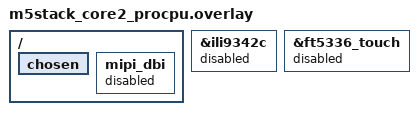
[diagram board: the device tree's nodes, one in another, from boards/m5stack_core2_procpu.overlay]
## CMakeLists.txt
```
# SPDX-License-Identifier: Apache-2.0

cmake_minimum_required(VERSION 3.20.0)

find_package(Zephyr REQUIRED HINTS $ENV{ZEPHYR_BASE})
project(dynamic_web)

zephyr_linker_sources(SECTIONS sections-rom.ld)
zephyr_linker_section(NAME http_resource_desc_web_http_service KVMA RAM_REGION GROUP RODATA_REGION)

set(gen_dir ${ZEPHYR_BINARY_DIR}/include/generated)
generate_inc_file_for_target(app web/index.html ${gen_dir}/web_index_html.inc)
generate_inc_file_for_target(app web/styles.css ${gen_dir}/web_styles_css.inc)
generate_inc_file_for_target(app web/app.js ${gen_dir}/web_app_js.inc)
generate_inc_file_for_target(app web/vendor/bootstrap/css/bootstrap.min.css ${gen_dir}/web_bootstrap_min_css_gz.inc --gzip)
generate_inc_file_for_target(app web/vendor/bootstrap/js/bootstrap.bundle.min.js ${gen_dir}/web_bootstrap_bundle_min_js_gz.inc --gzip)

target_sources(app PRIVATE
  src/app_utils.c
  src/main.c
  src/wifi_service.c
  src/filesystem_service.c
  src/webserver_service.c
)
```

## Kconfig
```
source "Kconfig.zephyr"

menu "dynamic_web options"

choice APP_WEB_CONTENT_SOURCE
	prompt "Web content source"
	default APP_WEB_CONTENT_FROM_FILESYSTEM

config APP_WEB_CONTENT_FROM_FILESYSTEM
	bool "Serve web files from LittleFS (/lfs/www)"

config APP_WEB_CONTENT_FROM_FIRMWARE
	bool "Serve web files directly from firmware image"

endchoice

config APP_SYNC_WEB_FILES_ON_BOOT
	bool "Sync embedded web files to LittleFS at boot"
	default y
	depends on APP_WEB_CONTENT_FROM_FILESYSTEM
	help
	  When enabled, website assets embedded in firmware are written
	  to /lfs/www on each boot. Disable this if you plan to update
	  files directly in LittleFS (e.g. via mcumgr) and want to keep
	  those changes across reboot.

endmenu
```

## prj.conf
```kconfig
CONFIG_MAIN_STACK_SIZE=6144

CONFIG_LOG=y
CONFIG_THREAD_RUNTIME_STATS=y
CONFIG_SCHED_THREAD_USAGE_ALL=y
CONFIG_SYS_HEAP_RUNTIME_STATS=y

CONFIG_NETWORKING=y
CONFIG_NET_MGMT=y
CONFIG_NET_MGMT_EVENT=y
CONFIG_NET_MGMT_EVENT_INFO=y
CONFIG_NET_CONNECTION_MANAGER=y
CONFIG_NET_IPV4=y
CONFIG_NET_TCP=y
CONFIG_NET_UDP=y
CONFIG_NET_SOCKETS=y
CONFIG_NET_DHCPV4=y

CONFIG_WIFI=y
CONFIG_NET_L2_WIFI_MGMT=y

CONFIG_HTTP_SERVER=y
CONFIG_HTTP_SERVER_RESOURCE_WILDCARD=y
CONFIG_HTTP_SERVER_COMPRESSION=y
CONFIG_HTTP_SERVER_NUM_SERVICES=1
CONFIG_HTTP_SERVER_MAX_CLIENTS=4
CONFIG_HTTP_SERVER_CLIENT_BUFFER_SIZE=2048

CONFIG_POSIX_API=y
CONFIG_EVENTFD=y
CONFIG_FDTABLE=y
CONFIG_ZVFS_POLL_MAX=16

CONFIG_FLASH=y
CONFIG_FLASH_MAP=y
CONFIG_FILE_SYSTEM=y
CONFIG_FILE_SYSTEM_MKFS=y
CONFIG_FILE_SYSTEM_LITTLEFS=y

CONFIG_ZCBOR=y
CONFIG_MCUMGR=y
CONFIG_MCUMGR_GRP_FS=y
CONFIG_MCUMGR_GRP_OS=y
CONFIG_BASE64=y
CONFIG_CRC=y
# CONFIG_MCUMGR_TRANSPORT_UART is not set
CONFIG_MCUMGR_TRANSPORT_SHELL=y
CONFIG_MCUMGR_TRANSPORT_NETBUF_COUNT=8
CONFIG_MCUMGR_TRANSPORT_NETBUF_SIZE=1024
CONFIG_MCUMGR_TRANSPORT_SHELL_MTU=512
CONFIG_MCUMGR_TRANSPORT_SHELL_RX_BUF_COUNT=4
CONFIG_MCUMGR_TRANSPORT_SHELL_INPUT_TIMEOUT=y
CONFIG_MCUMGR_TRANSPORT_SHELL_INPUT_TIMEOUT_TIME=10000
CONFIG_MCUMGR_TRANSPORT_WORKQUEUE_STACK_SIZE=3072
CONFIG_SYSTEM_WORKQUEUE_STACK_SIZE=2304

# CONFIG_APP_WEB_CONTENT_FROM_FIRMWARE=y
CONFIG_APP_WEB_CONTENT_FROM_FILESYSTEM=y
# important: do not overwrite uploaded files at boot
CONFIG_APP_SYNC_WEB_FILES_ON_BOOT=n
```

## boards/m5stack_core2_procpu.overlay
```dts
/* Disable display stack for this app on m5stack_core2_procpu. */

&ili9342c {
	status = "disabled";
};

&ft5336_touch {
	status = "disabled";
};

/ {
	chosen {
		/delete-property/ zephyr,display;
		/delete-property/ zephyr,touch;
	};

	mipi_dbi {
		status = "disabled";
	};
};
```

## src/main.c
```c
#include <zephyr/kernel.h>
#include <zephyr/logging/log.h>
#include <zephyr/net/net_ip.h>

#include "app_utils.h"
#include "filesystem_service.h"
#include "webserver_service.h"
#include "wifi_service.h"

LOG_MODULE_REGISTER(dynamic_web, LOG_LEVEL_INF);

#if defined(CONFIG_BOARD_M5STACK_CORE2_ESP32_APPCPU)
#error "This app requires Wi-Fi and must be built for m5stack_core2/esp32/procpu (not appcpu)."
#endif

int main(void)
{
	int ret;
	char ip[NET_IPV4_ADDR_LEN] = "0.0.0.0";
	struct webserver_status_provider provider = {
		.get_ipv4_addr = wifi_service_get_ipv4_addr,
		.get_ssid = wifi_service_get_ssid,
		.get_cpu_util_percent = app_utils_get_cpu_util_percent,
		.get_ram_util_percent = app_utils_get_ram_util_percent,
	};

	ret = wifi_service_init_and_connect();
	if (ret < 0) {
		return 0;
	}

#if defined(CONFIG_APP_WEB_CONTENT_FROM_FILESYSTEM)
	ret = filesystem_service_mount_or_format();
	if (ret < 0) {
		return 0;
	}

	ret = filesystem_service_sync_web_assets();
	if (ret < 0) {
		return 0;
	}
#endif

	ret = webserver_service_init(&provider);
	if (ret < 0) {
		LOG_ERR("Failed to init webserver service (%d)", ret);
		return 0;
	}

	ret = webserver_service_start();
	if (ret < 0) {
		LOG_ERR("Failed to start HTTP server (%d)", ret);
		return 0;
	}

	(void)wifi_service_get_ipv4_addr(ip, sizeof(ip));
	LOG_INF("HTTP server running at: http://%s/", ip);

	while (1) {
		wifi_service_process();
		k_sleep(K_MSEC(500));
	}
}
```

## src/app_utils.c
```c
#include "app_utils.h"

#include <zephyr/kernel.h>
#include <zephyr/sys/sys_heap.h>

int app_utils_get_cpu_util_percent(void)
{
#if defined(CONFIG_THREAD_RUNTIME_STATS) && defined(CONFIG_SCHED_THREAD_USAGE)
	k_thread_runtime_stats_t stats;
	int ret;

	ret = k_thread_runtime_stats_all_get(&stats);
	if (ret < 0) {
		return -1;
	}

	if (stats.execution_cycles == 0U) {
		return 0;
	}

	uint64_t pct = (stats.total_cycles * 100U) / stats.execution_cycles;
	if (pct > 100U) {
		pct = 100U;
	}

	return (int)pct;
#else
	return -1;
#endif
}

int app_utils_get_ram_util_percent(void)
{
#if defined(CONFIG_SYS_HEAP_RUNTIME_STATS)
	struct k_heap *heaps = NULL;
	struct sys_memory_stats stats;
	size_t total_alloc = 0U;
	size_t total_free = 0U;
	size_t total;
	int heap_count;
	int ret;

	heap_count = k_heap_array_get(&heaps);
	if ((heap_count <= 0) || (heaps == NULL)) {
		return -1;
	}

	for (int i = 0; i < heap_count; i++) {
		ret = sys_heap_runtime_stats_get(&heaps[i].heap, &stats);
		if (ret < 0) {
			continue;
		}

		total_alloc += stats.allocated_bytes;
		total_free += stats.free_bytes;
	}

	total = total_alloc + total_free;
	if (total == 0U) {
		return -1;
	}

	return (int)((total_alloc * 100U) / total);
#else
	return -1;
#endif
}
```

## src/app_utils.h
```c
#ifndef APP_UTILS_H
#define APP_UTILS_H

int app_utils_get_cpu_util_percent(void);
int app_utils_get_ram_util_percent(void);

#endif
```

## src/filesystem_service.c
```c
#include "filesystem_service.h"

#include <errno.h>

#include <zephyr/fs/fs.h>
#include <zephyr/fs/littlefs.h>
#include <zephyr/logging/log.h>
#include <zephyr/storage/flash_map.h>
#include <zephyr/sys/util.h>

LOG_MODULE_REGISTER(filesystem_service, LOG_LEVEL_INF);

FS_LITTLEFS_DECLARE_DEFAULT_CONFIG(storage);

static struct fs_mount_t web_fs_mount = {
	.type = FS_LITTLEFS,
	.mnt_point = FILESYSTEM_WEB_MOUNT_POINT,
	.storage_dev = (void *)FIXED_PARTITION_ID(storage_partition),
	.fs_data = &storage,
};

static const uint8_t web_index_html[] = {
#include "web_index_html.inc"
};

static const uint8_t web_styles_css[] = {
#include "web_styles_css.inc"
};

static const uint8_t web_app_js[] = {
#include "web_app_js.inc"
};

static const uint8_t web_bootstrap_min_css_gz[] = {
#include "web_bootstrap_min_css_gz.inc"
};

static const uint8_t web_bootstrap_bundle_min_js_gz[] = {
#include "web_bootstrap_bundle_min_js_gz.inc"
};

struct web_asset {
	const char *path;
	const uint8_t *data;
	size_t len;
};

static const struct web_asset web_assets[] = {
	{ FILESYSTEM_WEB_FS_PATH "/index.html", web_index_html, sizeof(web_index_html) },
	{ FILESYSTEM_WEB_FS_PATH "/styles.css", web_styles_css, sizeof(web_styles_css) },
	{ FILESYSTEM_WEB_FS_PATH "/app.js", web_app_js, sizeof(web_app_js) },
	{ FILESYSTEM_WEB_FS_PATH "/vendor/bootstrap/css/bootstrap.min.css.gz", web_bootstrap_min_css_gz,
	  sizeof(web_bootstrap_min_css_gz) },
	{ FILESYSTEM_WEB_FS_PATH "/vendor/bootstrap/js/bootstrap.bundle.min.js.gz",
	  web_bootstrap_bundle_min_js_gz, sizeof(web_bootstrap_bundle_min_js_gz) },
};

static int write_asset_to_fs(const struct web_asset *asset)
{
	struct fs_file_t file;
	ssize_t bytes_written;
	int ret;

	fs_file_t_init(&file);

	ret = fs_open(&file, asset->path, FS_O_CREATE | FS_O_WRITE | FS_O_TRUNC);
	if (ret < 0) {
		LOG_ERR("Failed to open %s (%d)", asset->path, ret);
		return ret;
	}

	bytes_written = fs_write(&file, asset->data, asset->len);
	if (bytes_written < 0) {
		LOG_ERR("Write failed for %s (%d)", asset->path, (int)bytes_written);
		(void)fs_close(&file);
		return (int)bytes_written;
	}

	if ((size_t)bytes_written != asset->len) {
		LOG_ERR("Short write for %s (%d/%d)", asset->path, (int)bytes_written,
			(int)asset->len);
		(void)fs_close(&file);
		return -EIO;
	}

	ret = fs_close(&file);
	if (ret < 0) {
		LOG_ERR("Failed to close %s (%d)", asset->path, ret);
		return ret;
	}

	return 0;
}

static int ensure_directory(const char *path)
{
	struct fs_dirent entry;
	int ret;

	ret = fs_stat(path, &entry);
	if (ret < 0) {
		ret = fs_mkdir(path);
		if (ret < 0) {
			LOG_ERR("Failed to create %s (%d)", path, ret);
			return ret;
		}
		return 0;
	}

	if (entry.type != FS_DIR_ENTRY_DIR) {
		LOG_ERR("%s exists but is not a directory", path);
		return -ENOTDIR;
	}

	return 0;
}

int filesystem_service_mount_or_format(void)
{
	int ret;

	ret = fs_mount(&web_fs_mount);
	if (ret == 0) {
		LOG_INF("Mounted LittleFS at %s", FILESYSTEM_WEB_MOUNT_POINT);
		return 0;
	}

	LOG_WRN("Mount failed (%d), formatting storage partition", ret);
	ret = fs_mkfs(FS_LITTLEFS, (uintptr_t)web_fs_mount.storage_dev, web_fs_mount.fs_data, 0);
	if (ret < 0) {
		LOG_ERR("LittleFS format failed (%d)", ret);
		return ret;
	}

	ret = fs_mount(&web_fs_mount);
	if (ret < 0) {
		LOG_ERR("Mount after format failed (%d)", ret);
		return ret;
	}

	LOG_INF("Mounted formatted LittleFS at %s", FILESYSTEM_WEB_MOUNT_POINT);
	return 0;
}

int filesystem_service_sync_web_assets(void)
{
	int ret;

	if (!IS_ENABLED(CONFIG_APP_SYNC_WEB_FILES_ON_BOOT)) {
		LOG_INF("Web asset sync disabled (CONFIG_APP_SYNC_WEB_FILES_ON_BOOT=n)");
		return 0;
	}

	ret = ensure_directory(FILESYSTEM_WEB_FS_PATH);
	if (ret < 0) {
		return ret;
	}

	ret = ensure_directory(FILESYSTEM_WEB_FS_PATH "/vendor");
	if (ret < 0) {
		return ret;
	}

	ret = ensure_directory(FILESYSTEM_WEB_FS_PATH "/vendor/bootstrap");
	if (ret < 0) {
		return ret;
	}

	ret = ensure_directory(FILESYSTEM_WEB_FS_PATH "/vendor/bootstrap/css");
	if (ret < 0) {
		return ret;
	}

	ret = ensure_directory(FILESYSTEM_WEB_FS_PATH "/vendor/bootstrap/js");
	if (ret < 0) {
		return ret;
	}

	for (size_t i = 0; i < ARRAY_SIZE(web_assets); i++) {
		ret = write_asset_to_fs(&web_assets[i]);
		if (ret < 0) {
			return ret;
		}
	}

	LOG_INF("Web assets synced to %s", FILESYSTEM_WEB_FS_PATH);
	return 0;
}
```

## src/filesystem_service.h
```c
#ifndef FILESYSTEM_SERVICE_H
#define FILESYSTEM_SERVICE_H

#define FILESYSTEM_WEB_MOUNT_POINT "/lfs"
#define FILESYSTEM_WEB_FS_PATH     FILESYSTEM_WEB_MOUNT_POINT "/www"

int filesystem_service_mount_or_format(void);
int filesystem_service_sync_web_assets(void);

#endif
```

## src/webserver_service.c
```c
#include "webserver_service.h"

#include <errno.h>
#include <stddef.h>

#include <zephyr/kernel.h>
#include <zephyr/logging/log.h>
#include <zephyr/net/http/server.h>
#include <zephyr/net/http/service.h>
#include <zephyr/net/net_ip.h>

#include "filesystem_service.h"

LOG_MODULE_REGISTER(webserver_service, LOG_LEVEL_INF);

static struct webserver_status_provider status_provider;
static uint16_t http_port = 80;

static int api_status_handler(struct http_client_ctx *client, enum http_data_status status,
			      const struct http_request_ctx *request_ctx,
			      struct http_response_ctx *response_ctx, void *user_data)
{
	static uint8_t payload[320];
	char ip[NET_IPV4_ADDR_LEN] = "0.0.0.0";
	const char *ssid = "unknown";
	int cpu_load_percent = -1;
	int ram_util_percent = -1;
	int len;

	ARG_UNUSED(client);
	ARG_UNUSED(request_ctx);
	ARG_UNUSED(user_data);

	if (status == HTTP_SERVER_DATA_ABORTED) {
		return 0;
	}

	if (status == HTTP_SERVER_DATA_FINAL) {
		if (status_provider.get_ipv4_addr != NULL) {
			(void)status_provider.get_ipv4_addr(ip, sizeof(ip));
		}

		if (status_provider.get_ssid != NULL) {
			ssid = status_provider.get_ssid();
		}

		if (status_provider.get_cpu_util_percent != NULL) {
			cpu_load_percent = status_provider.get_cpu_util_percent();
		}

		if (status_provider.get_ram_util_percent != NULL) {
			ram_util_percent = status_provider.get_ram_util_percent();
		}

		len = snprintk((char *)payload, sizeof(payload),
			       "{\"uptime_ms\":%lld,\"ip\":\"%s\",\"ssid\":\"%s\",\"cpu_load_percent\":%d,\"ram_util_percent\":%d}",
			       (long long)k_uptime_get(), ip, ssid, cpu_load_percent, ram_util_percent);
		if (len < 0) {
			return len;
		}

		if (len >= (int)sizeof(payload)) {
			len = sizeof(payload) - 1;
		}

		response_ctx->body = payload;
		response_ctx->body_len = (size_t)len;
		response_ctx->final_chunk = true;
	}

	return 0;
}

static struct http_resource_detail_dynamic api_status_detail = {
	.common = {
		.type = HTTP_RESOURCE_TYPE_DYNAMIC,
		.bitmask_of_supported_http_methods = BIT(HTTP_GET),
		.content_type = "application/json",
	},
	.cb = api_status_handler,
	.user_data = NULL,
};

#if defined(CONFIG_APP_WEB_CONTENT_FROM_FILESYSTEM)
static struct http_resource_detail_static_fs web_fs_detail = {
	.common = {
		.type = HTTP_RESOURCE_TYPE_STATIC_FS,
		.bitmask_of_supported_http_methods = BIT(HTTP_GET),
	},
	.fs_path = FILESYSTEM_WEB_FS_PATH,
};
#else
static const uint8_t web_index_html[] = {
#include "web_index_html.inc"
};

static const uint8_t web_styles_css[] = {
#include "web_styles_css.inc"
};

static const uint8_t web_app_js[] = {
#include "web_app_js.inc"
};

static const uint8_t web_bootstrap_min_css_gz[] = {
#include "web_bootstrap_min_css_gz.inc"
};

static const uint8_t web_bootstrap_bundle_min_js_gz[] = {
#include "web_bootstrap_bundle_min_js_gz.inc"
};

static struct http_resource_detail_static web_index_detail = {
	.common = {
		.type = HTTP_RESOURCE_TYPE_STATIC,
		.bitmask_of_supported_http_methods = BIT(HTTP_GET),
		.content_type = "text/html",
	},
	.static_data = web_index_html,
	.static_data_len = sizeof(web_index_html),
};

static struct http_resource_detail_static web_styles_detail = {
	.common = {
		.type = HTTP_RESOURCE_TYPE_STATIC,
		.bitmask_of_supported_http_methods = BIT(HTTP_GET),
		.content_type = "text/css",
	},
	.static_data = web_styles_css,
	.static_data_len = sizeof(web_styles_css),
};

static struct http_resource_detail_static web_app_js_detail = {
	.common = {
		.type = HTTP_RESOURCE_TYPE_STATIC,
		.bitmask_of_supported_http_methods = BIT(HTTP_GET),
		.content_type = "text/javascript",
	},
	.static_data = web_app_js,
	.static_data_len = sizeof(web_app_js),
};

static struct http_resource_detail_static web_bootstrap_css_detail = {
	.common = {
		.type = HTTP_RESOURCE_TYPE_STATIC,
		.bitmask_of_supported_http_methods = BIT(HTTP_GET),
		.content_type = "text/css",
		.content_encoding = "gzip",
	},
	.static_data = web_bootstrap_min_css_gz,
	.static_data_len = sizeof(web_bootstrap_min_css_gz),
};

static struct http_resource_detail_static web_bootstrap_js_detail = {
	.common = {
		.type = HTTP_RESOURCE_TYPE_STATIC,
		.bitmask_of_supported_http_methods = BIT(HTTP_GET),
		.content_type = "text/javascript",
		.content_encoding = "gzip",
	},
	.static_data = web_bootstrap_bundle_min_js_gz,
	.static_data_len = sizeof(web_bootstrap_bundle_min_js_gz),
};
#endif

HTTP_SERVICE_DEFINE(web_http_service, NULL, &http_port, 4, 8, NULL, NULL, NULL);
HTTP_RESOURCE_DEFINE(api_status_resource, web_http_service, "/api/status", &api_status_detail);
#if defined(CONFIG_APP_WEB_CONTENT_FROM_FILESYSTEM)
HTTP_RESOURCE_DEFINE(web_fs_resource, web_http_service, "/*", &web_fs_detail);
#else
HTTP_RESOURCE_DEFINE(web_index_resource, web_http_service, "/", &web_index_detail);
HTTP_RESOURCE_DEFINE(web_styles_resource, web_http_service, "/styles.css", &web_styles_detail);
HTTP_RESOURCE_DEFINE(web_app_js_resource, web_http_service, "/app.js", &web_app_js_detail);
HTTP_RESOURCE_DEFINE(web_bootstrap_css_resource, web_http_service,
		     "/vendor/bootstrap/css/bootstrap.min.css", &web_bootstrap_css_detail);
HTTP_RESOURCE_DEFINE(web_bootstrap_js_resource, web_http_service,
		     "/vendor/bootstrap/js/bootstrap.bundle.min.js", &web_bootstrap_js_detail);
#endif

int webserver_service_init(const struct webserver_status_provider *provider)
{
	if (provider == NULL) {
		return -EINVAL;
	}

	status_provider = *provider;
	return 0;
}

int webserver_service_start(void)
{
	return http_server_start();
}
```

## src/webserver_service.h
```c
#ifndef WEBSERVER_SERVICE_H
#define WEBSERVER_SERVICE_H

#include <stddef.h>

struct webserver_status_provider {
	int (*get_ipv4_addr)(char *buf, size_t buf_len);
	const char *(*get_ssid)(void);
	int (*get_cpu_util_percent)(void);
	int (*get_ram_util_percent)(void);
};

int webserver_service_init(const struct webserver_status_provider *provider);
int webserver_service_start(void);

#endif
```

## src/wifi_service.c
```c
#include "wifi_service.h"

#include <errno.h>
#include <stdbool.h>
#include <string.h>

#include <zephyr/kernel.h>
#include <zephyr/logging/log.h>
#include <zephyr/net/dhcpv4.h>
#include <zephyr/net/net_event.h>
#include <zephyr/net/net_if.h>
#include <zephyr/net/net_ip.h>
#include <zephyr/net/net_mgmt.h>
#include <zephyr/net/wifi_mgmt.h>

#include "wifi_secrets.h"

LOG_MODULE_REGISTER(wifi_service, LOG_LEVEL_INF);

static struct net_if *wifi_iface;
static struct net_mgmt_event_callback wifi_mgmt_cb;
static struct net_mgmt_event_callback dhcp_mgmt_cb;
static int wifi_connect_result = -EAGAIN;
static bool reconnect_requested;
static bool wifi_ready;
static int64_t last_reconnect_attempt;
static struct wifi_connect_req_params wifi_params;

K_SEM_DEFINE(wifi_connected_sem, 0, 1);
K_SEM_DEFINE(ipv4_addr_sem, 0, 1);

int wifi_service_get_ipv4_addr(char *buf, size_t buf_len)
{
	struct in_addr *addr;

	if (wifi_iface == NULL) {
		return -ENODEV;
	}

	addr = net_if_ipv4_get_global_addr(wifi_iface, NET_ADDR_PREFERRED);
	if (addr == NULL) {
		return -EADDRNOTAVAIL;
	}

	if (net_addr_ntop(AF_INET, addr, buf, buf_len) == NULL) {
		return -EINVAL;
	}

	return 0;
}

const char *wifi_service_get_ssid(void)
{
	return WIFI_SSID;
}

static void wifi_mgmt_handler(struct net_mgmt_event_callback *cb, uint64_t mgmt_event,
			      struct net_if *iface)
{
	ARG_UNUSED(iface);

	if (mgmt_event == NET_EVENT_WIFI_CONNECT_RESULT) {
		const struct wifi_status *status = (const struct wifi_status *)cb->info;

		if (status != NULL) {
			wifi_connect_result = status->status;
		} else {
			wifi_connect_result = -EIO;
		}

		if (wifi_connect_result == 0) {
			LOG_INF("Wi-Fi connected to SSID: %s", WIFI_SSID);
			reconnect_requested = false;
			wifi_ready = false;
			net_dhcpv4_start(wifi_iface);
		} else {
			LOG_ERR("Wi-Fi connection failed (%d)", wifi_connect_result);
			reconnect_requested = true;
		}
		k_sem_give(&wifi_connected_sem);
		return;
	}

	if (mgmt_event == NET_EVENT_WIFI_DISCONNECT_RESULT) {
		LOG_WRN("Wi-Fi disconnected, scheduling reconnect");
		reconnect_requested = true;
		wifi_ready = false;
	}
}

static void dhcp_mgmt_handler(struct net_mgmt_event_callback *cb, uint64_t mgmt_event,
			      struct net_if *iface)
{
	char ip[NET_IPV4_ADDR_LEN] = { 0 };

	ARG_UNUSED(cb);

	if (iface != wifi_iface) {
		return;
	}

	if ((mgmt_event & NET_EVENT_IPV4_DHCP_BOUND) || (mgmt_event & NET_EVENT_IPV4_ADDR_ADD)) {
		if (wifi_service_get_ipv4_addr(ip, sizeof(ip)) == 0) {
			LOG_INF("IPv4 ready: %s", ip);
		}
		wifi_ready = true;
		reconnect_requested = false;
		if (k_sem_count_get(&ipv4_addr_sem) == 0) {
			k_sem_give(&ipv4_addr_sem);
		}
	}
}

static int request_wifi_connect(void)
{
	int ret;

	ret = net_mgmt(NET_REQUEST_WIFI_CONNECT, wifi_iface, &wifi_params, sizeof(wifi_params));
	if (ret == -EALREADY) {
		LOG_INF("Wi-Fi connect request already active");
		return 0;
	}

	if (ret < 0) {
		LOG_ERR("NET_REQUEST_WIFI_CONNECT failed (%d)", ret);
	}

	return ret;
}

static int connect_to_wifi(void)
{
	int ret;
	int attempt;
	const size_t ssid_len = strlen(WIFI_SSID);
	const size_t psk_len = strlen(WIFI_PSK);

	if (ssid_len == 0U) {
		LOG_ERR("WIFI_SSID is empty in src/wifi_secrets.h");
		return -EINVAL;
	}

	memset(&wifi_params, 0, sizeof(wifi_params));
	wifi_params.ssid = (const uint8_t *)WIFI_SSID;
	wifi_params.ssid_length = ssid_len;
	wifi_params.channel = WIFI_CHANNEL_ANY;
	wifi_params.band = WIFI_FREQ_BAND_2_4_GHZ;
	if (psk_len == 0U) {
		wifi_params.security = WIFI_SECURITY_TYPE_NONE;
		wifi_params.psk = NULL;
		wifi_params.psk_length = 0U;
	} else {
		wifi_params.security = WIFI_SECURITY_TYPE_PSK;
		wifi_params.psk = (const uint8_t *)WIFI_PSK;
		wifi_params.psk_length = psk_len;
	}

	for (attempt = 1; attempt <= 5; attempt++) {
		wifi_connect_result = -EAGAIN;
		wifi_ready = false;
		k_sem_reset(&wifi_connected_sem);
		k_sem_reset(&ipv4_addr_sem);

		LOG_INF("Connecting to Wi-Fi SSID: %s (attempt %d/5)", WIFI_SSID, attempt);
		ret = request_wifi_connect();
		if (ret < 0) {
			k_sleep(K_SECONDS(2));
			continue;
		}

		if (wifi_service_get_ipv4_addr((char[NET_IPV4_ADDR_LEN]){0}, NET_IPV4_ADDR_LEN) == 0) {
			wifi_connect_result = 0;
			wifi_ready = true;
			return 0;
		}

		ret = k_sem_take(&wifi_connected_sem, K_SECONDS(20));
		if (ret < 0) {
			LOG_ERR("Timed out waiting for Wi-Fi connect result");
			k_sleep(K_SECONDS(2));
			continue;
		}

		if (wifi_connect_result != 0) {
			LOG_ERR("Wi-Fi association/authentication failed (%d)", wifi_connect_result);
			k_sleep(K_SECONDS(2));
			continue;
		}

		LOG_INF("Waiting for DHCP IPv4 lease");
		ret = k_sem_take(&ipv4_addr_sem, K_SECONDS(30));
		if (ret == 0 && wifi_ready) {
			return 0;
		}

		if (wifi_service_get_ipv4_addr((char[NET_IPV4_ADDR_LEN]){0}, NET_IPV4_ADDR_LEN) == 0) {
			wifi_ready = true;
			return 0;
		}

		LOG_ERR("Timed out waiting for IPv4 address");
		k_sleep(K_SECONDS(2));
	}

	return -ETIMEDOUT;
}

int wifi_service_init_and_connect(void)
{
	int ret;

	wifi_iface = net_if_get_wifi_sta();
	if (wifi_iface == NULL) {
		wifi_iface = net_if_get_default();
	}

	if (wifi_iface == NULL) {
		LOG_ERR("No Wi-Fi network interface found");
		return -ENODEV;
	}

	if (!net_if_is_wifi(wifi_iface)) {
		LOG_ERR("Selected default interface is not a Wi-Fi interface");
		return -ENODEV;
	}

	if (!net_if_is_up(wifi_iface)) {
		ret = net_if_up(wifi_iface);
		if ((ret < 0) && (ret != -EALREADY)) {
			LOG_ERR("Failed to bring Wi-Fi interface up (%d)", ret);
			return ret;
		}
	}

	net_mgmt_init_event_callback(&wifi_mgmt_cb, wifi_mgmt_handler,
				     NET_EVENT_WIFI_CONNECT_RESULT |
					     NET_EVENT_WIFI_DISCONNECT_RESULT);
	net_mgmt_add_event_callback(&wifi_mgmt_cb);

	net_mgmt_init_event_callback(&dhcp_mgmt_cb, dhcp_mgmt_handler,
				     NET_EVENT_IPV4_DHCP_BOUND | NET_EVENT_IPV4_ADDR_ADD);
	net_mgmt_add_event_callback(&dhcp_mgmt_cb);

	return connect_to_wifi();
}

void wifi_service_process(void)
{
	int64_t now_ms = k_uptime_get();

	if (!reconnect_requested) {
		return;
	}

	if ((now_ms - last_reconnect_attempt) < 3000) {
		return;
	}

	LOG_INF("Attempting Wi-Fi reconnect");
	(void)request_wifi_connect();
	last_reconnect_attempt = now_ms;
}
```

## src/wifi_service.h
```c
#ifndef WIFI_SERVICE_H
#define WIFI_SERVICE_H

#include <stddef.h>

int wifi_service_init_and_connect(void);
void wifi_service_process(void);
int wifi_service_get_ipv4_addr(char *buf, size_t buf_len);
const char *wifi_service_get_ssid(void);

#endif
```
